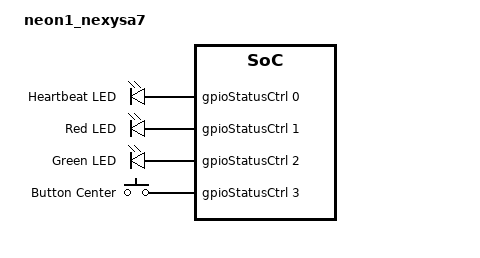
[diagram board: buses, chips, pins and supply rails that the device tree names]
/dts-v1/;
#include <elements/neon1.dtsi>

/ {
	model = "neon1_nexysa7";
	compatible = "elements,neon1_nexysa7";

	chosen {
		zephyr,console = &uartStdCtrl;
		zephyr,shell-uart = &uartStdCtrl;
		zephyr,sram = &ram0;
	};

	leds {
		compatible = "gpio-leds";
		heartbeat: HEARTBEAT {
			gpios = <&gpioStatusCtrl 0 GPIO_ACTIVE_HIGH>;
			label = "Heartbeat LED";
		};

		red: RED {
			gpios = <&gpioStatusCtrl 1 GPIO_ACTIVE_HIGH>;
			label = "Red LED";
		};

		green: GREEN {
			gpios = <&gpioStatusCtrl 2 GPIO_ACTIVE_HIGH>;
			label = "Green LED";
		};
	};

	keys {
		compatible = "gpio-keys";
		btnc: sw0 {
			gpios = <&gpioStatusCtrl 3 GPIO_ACTIVE_HIGH>;
			label = "Button Center";
		};
	};
};

&uartStdCtrl {
	clock-frequency = <100000000>;
};
